# apollo2 register map
Vendor: Ambiq Micro; Series: Apollo; File version: 1.0
CPU: CM4 r1p0, little endian, MPU, FPU, 3 interrupt priority bits
Registers are 32-bit, read-write, reset 0x0 unless marked. A register's access mark holds for its fields unless they carry their own. Offsets are from the block's base; [hi:lo] are bit positions; 'fields as' and 'values as' point back to an identical list.

## IOSLAVE — I2C/SPI Slave
Base 0x50000000
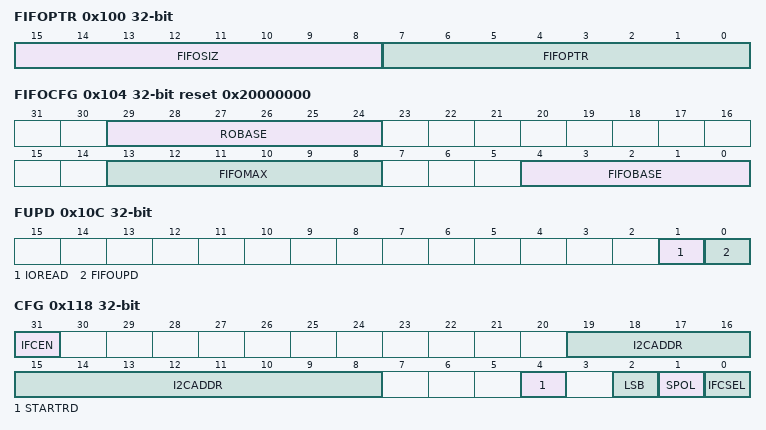
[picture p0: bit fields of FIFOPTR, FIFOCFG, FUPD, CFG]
0x100 FIFOPTR — Current FIFO Pointer
  [15:8] FIFOSIZ — The number of bytes currently in the hardware FIFO.
  [7:0] FIFOPTR — Current FIFO pointer.
0x104 FIFOCFG reset 0x20000000 — FIFO Configuration
  [29:24] ROBASE — Defines the read-only area. The IO Slave read-only area is situated in LRAM at (ROBASE*8) to (FIFOOBASE*8-1)
  [13:8] FIFOMAX — These bits hold the maximum FIFO address in 8 byte segments. It is also the beginning of the RAM area of the LRAM. Note that no RAM area is configured if FIFOMAX is set to 0x1F.
  [4:0] FIFOBASE — These bits hold the base address of the I/O FIFO in 8 byte segments. The IO Slave FIFO is situated in LRAM at (FIFOBASE*8) to (FIFOMAX*8-1).
0x108 FIFOTHR — FIFO Threshold Configuration
  [7:0] FIFOTHR — FIFO size interrupt threshold.
0x10C FUPD — FIFO Update Status
  [1] IOREAD — This bitfield indicates an IO read is active.
  [0] FIFOUPD — This bit indicates that a FIFO update is underway.
0x110 FIFOCTR — Overall FIFO Counter
  [9:0] FIFOCTR — Virtual FIFO byte count
0x114 FIFOINC — Overall FIFO Counter Increment
  [9:0] FIFOINC — Increment the Overall FIFO Counter by this value on a write
0x118 CFG — I/O Slave Configuration
  [31] IFCEN — IOSLAVE interface enable.
    0=DIS (Disable the IOSLAVE value.); 1=EN (Enable the IOSLAVE value.)
  [19:8] I2CADDR — 7-bit or 10-bit I2C device address.
  [4] STARTRD — This bit holds the cycle to initiate an I/O RAM read.
    0=LATE (Initiate I/O RAM read late in each transferred byte. value.); 1=EARLY (Initiate I/O RAM read early in each transferred byte. value.)
  [2] LSB — This bit selects the transfer bit ordering.
    0=MSB_FIRST (Data is assumed to be sent and received with MSB first. value.); 1=LSB_FIRST (Data is assumed to be sent and received with LSB first. value.)
  [1] SPOL — This bit selects SPI polarity.
    0=SPI_MODES_0_3 (Polarity 0, handles SPI modes 0 and 3. value.); 1=SPI_MODES_1_2 (Polarity 1, handles SPI modes 1 and 2. value.)
  [0] IFCSEL — This bit selects the I/O interface.
    0=I2C (Selects I2C interface for the IO Slave. value.); 1=SPI (Selects SPI interface for the IO Slave. value.)
0x11C PRENC — I/O Slave Interrupt Priority Encode
  [4:0] PRENC — These bits hold the priority encode of the REGACC interrupts.
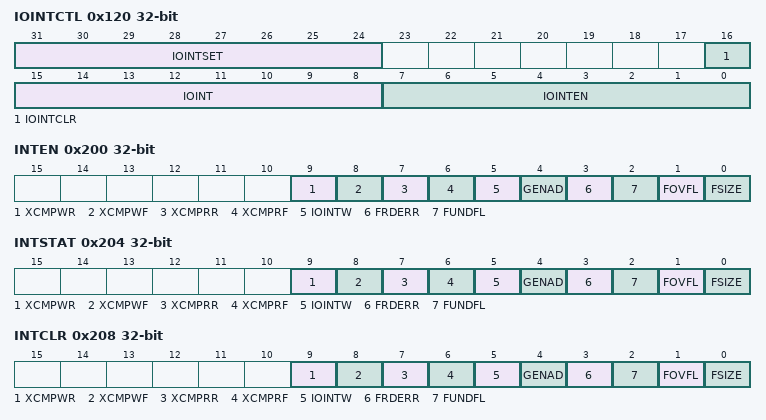
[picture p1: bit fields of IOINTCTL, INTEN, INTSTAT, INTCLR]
0x120 IOINTCTL — I/O Interrupt Control
  [31:24] IOINTSET — These bits set the IOINT interrupts when written with a 1.
  [16] IOINTCLR — This bit clears all of the IOINT interrupts when written with a 1.
  [15:8] IOINT — These bits read the IOINT interrupts.
  [7:0] IOINTEN — These read-only bits indicate whether the IOINT interrupts are enabled.
0x124 GENADD — General Address Data
  [7:0] GADATA — The data supplied on the last General Address reference.
0x200 INTEN — IO Slave Interrupts: Enable
  [9] XCMPWR — Transfer complete interrupt, write to register space.
  [8] XCMPWF — Transfer complete interrupt, write to FIFO space.
  [7] XCMPRR — Transfer complete interrupt, read from register space.
  [6] XCMPRF — Transfer complete interrupt, read from FIFO space.
  [5] IOINTW — I2C Interrupt Write interrupt.
  [4] GENAD — I2C General Address interrupt.
  [3] FRDERR — FIFO Read Error interrupt.
  [2] FUNDFL — FIFO Underflow interrupt.
  [1] FOVFL — FIFO Overflow interrupt.
  [0] FSIZE — FIFO Size interrupt.
0x204 INTSTAT — IO Slave Interrupts: Status
  fields as INTEN
0x208 INTCLR — IO Slave Interrupts: Clear
  fields as INTEN
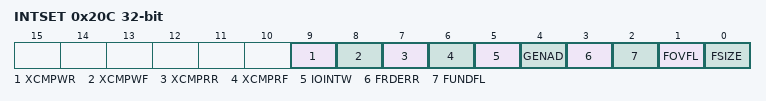
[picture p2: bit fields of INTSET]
0x20C INTSET — IO Slave Interrupts: Set
  fields as INTEN
0x210 REGACCINTEN — Register Access Interrupts: Enable
  [31:0] REGACC — Register access interrupts.
0x214 REGACCINTSTAT — Register Access Interrupts: Status
  [31:0] REGACC — Register access interrupts.
0x218 REGACCINTCLR — Register Access Interrupts: Clear
  [31:0] REGACC — Register access interrupts.
0x21C REGACCINTSET — Register Access Interrupts: Set
  [31:0] REGACC — Register access interrupts.
